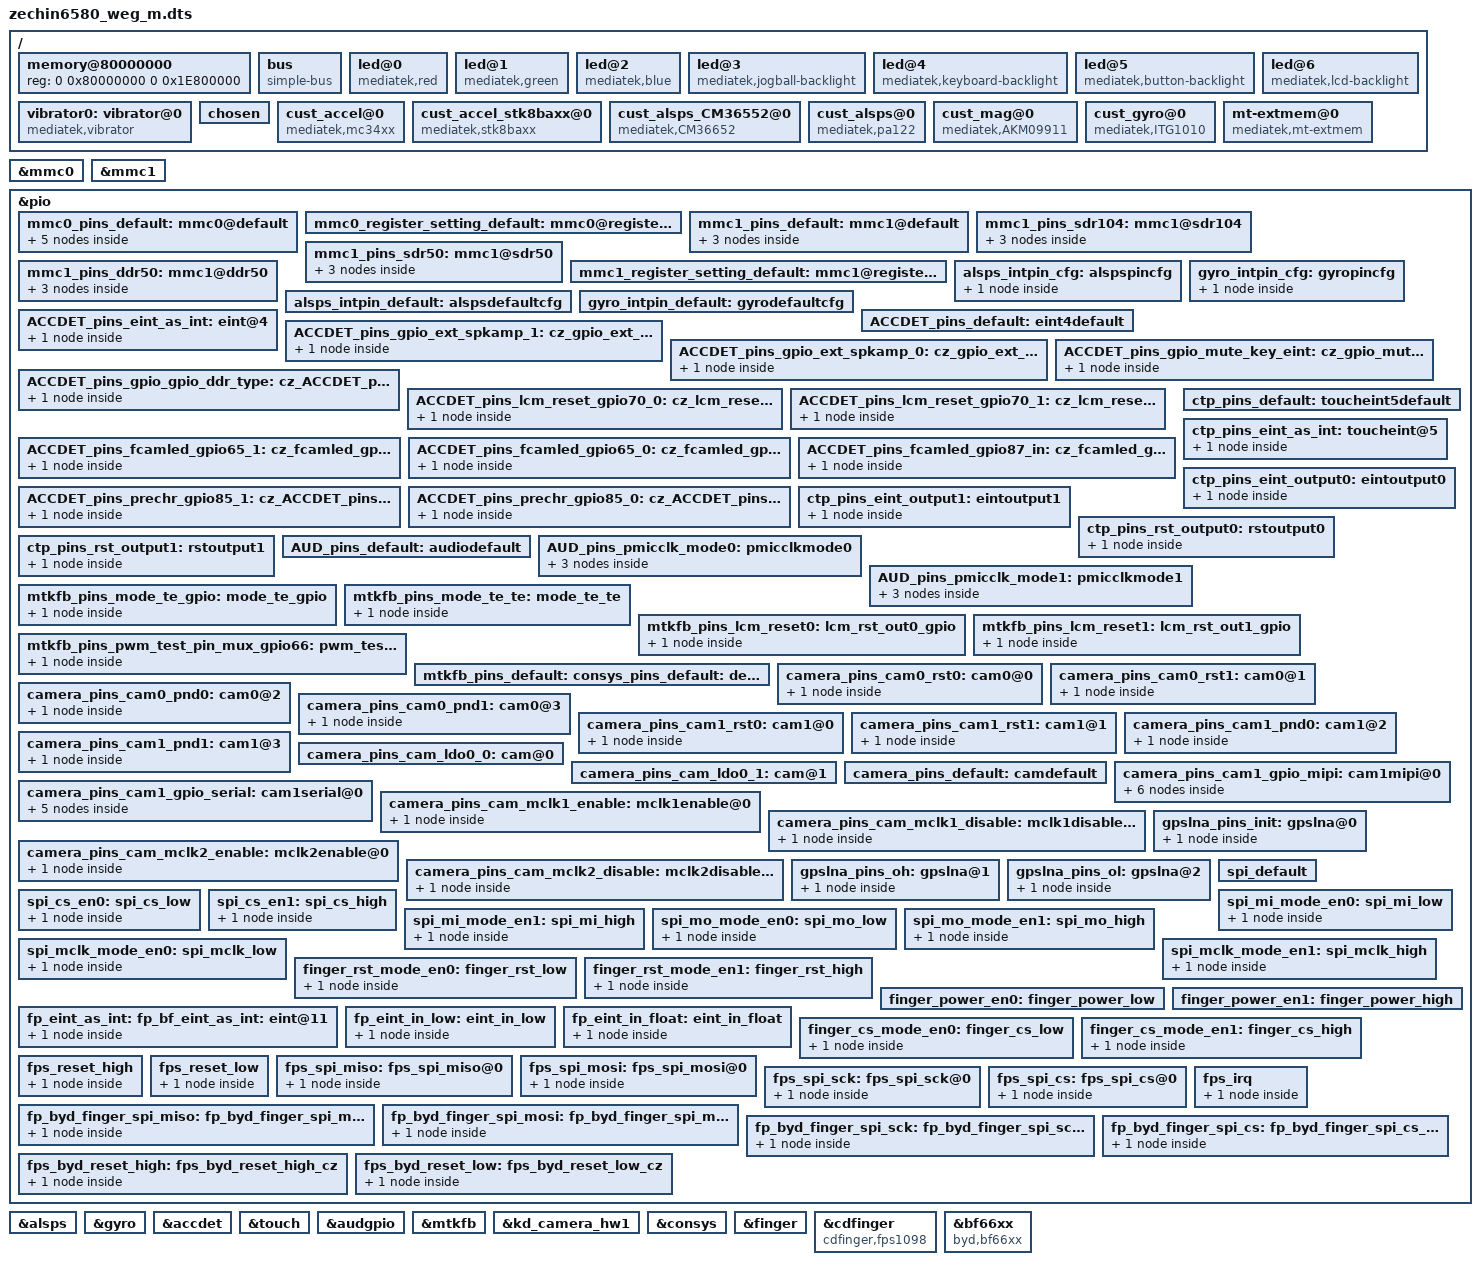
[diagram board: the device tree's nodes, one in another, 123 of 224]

/dts-v1/;

#include "mt6580.dtsi"

/ {
	memory@80000000 {
		device_type = "memory";
		reg = <0 0x80000000 0 0x1E800000>;
	};

	bus {
		compatible = "simple-bus";
		#address-cells = <1>;
		#size-cells = <1>;
		ranges = <0 0 0 0xffffffff>;
	};

	led@0 {
		compatible = "mediatek,red";
		led_mode = <0>;
		data = <1>;
		pwm_config = <0 0 0 0 0>;
	};
	led@1 {
		compatible = "mediatek,green";
		led_mode = <0>;
		data = <1>;
		pwm_config = <0 0 0 0 0>;
	};
	led@2 {
		compatible = "mediatek,blue";
		led_mode = <0>;
		data = <1>;
		pwm_config = <0 0 0 0 0>;
	};
	led@3 {
		compatible = "mediatek,jogball-backlight";
		led_mode = <0>;
		data = <1>;
		pwm_config = <0 0 0 0 0>;
	};
	led@4 {
		compatible = "mediatek,keyboard-backlight";
		led_mode = <0>;
		data = <1>;
		pwm_config = <0 0 0 0 0>;
	};
	led@5 {
		compatible = "mediatek,button-backlight";
		led_mode = <0>;
		data = <1>;
		pwm_config = <0 0 0 0 0>;
	};
	led@6 {
		compatible = "mediatek,lcd-backlight";
		led_mode = <5>;
		data = <1>;
		pwm_config = <0 0 0 0 0>;
	};
	vibrator0:vibrator@0 {
		compatible = "mediatek,vibrator";
		vib_timer = <25>;
		vib_limit = <9>;
		vib_vol= <7>;
	};

	   /* chosen */
	   chosen {
	bootargs = "console=tty0 console=ttyMT0,921600n1 root=/dev/ram initrd=0x84000000,0x400000 loglevel=8";
		/* fpga may has no lk, we need to specify display info here */
		/* fb buffer is reserved using this dts by memory node above */
		atag,videolfb-fb_base = <0x9E800000>;
		atag,videolfb-islcmfound = <1>;
		atag,videolfb-fps= <6000>;
		atag,videolfb-vramSize= <0x01800000>;
		atag,videolfb-lcmname= "nt35590_AUO";
	   };
	 /*  start sensor cz mod direction from 2 to 3(h339_80) s89 */
	 /*  start sensor */
		cust_accel@0 {
		compatible				= "mediatek,MC3410";
		i2c_num				= <2>;
		i2c_addr				= <0x4c 0 0 0>;
		direction				= <2>;
		power_id				= <0xffff>;
		power_vol				= <0>;
		firlen					= <0>;
		is_batch_supported			= <0>;
			};


		cust_accel@0 {
		compatible				= "mediatek,MC3XXX";
		i2c_num				= <2>;
		i2c_addr				= <0x4c 0 0 0>;
		direction				= <6>;
		power_id				= <0xffff>;
		power_vol				= <0>;
		firlen					= <0>;
		is_batch_supported			= <0>;
			};

/* sensor standardization */

	cust_accel@0 {
		compatible 				= "mediatek,mc34xx";
		i2c_num 				= <2>;
		i2c_addr 				= <0x4c 0 0 0>;
		direction 				= <0>;
		power_id 				= <0xffff>;
		power_vol 				= <0>;
		firlen					= <0>;
		is_batch_supported		= <0>;
	};

			/* 4 before */
		cust_accel_stk8baxx@0 {
		compatible				= "mediatek,stk8baxx";
		i2c_num				= <2>;
		i2c_addr				= <0x18 0 0 0>;
		direction				= <0>;
		power_id				= <0xffff>;
		power_vol				= <0>;
		firlen					= <2>;
		is_batch_supported			= <0>;
			};

		cust_alsps_CM36552@0 {
		compatible				= "mediatek,CM36652";
		i2c_num				= <2>;
		i2c_addr				= <0x60 0 0 0>;
		polling_mode_ps			= <0>;
		polling_mode_als		= <1>;
		power_id				= <0xffff>;
		power_vol				= <0>;
/* Total has 15 level*/
	als_level = <0 125 319 525 1091 2480 3058 5115 8589 10769 12857 17807 22091 65535 65535>;
/*  Total has 16 range*/
	als_value = <0 133 303 504 1002 2003 3006 5003 8002 10000 12000 16000 20000 20000 20000 20000>;
		ps_threshold_high		=  <26>;
		ps_threshold_low		=  <21>;
		is_batch_supported_ps	= <0>;
		is_batch_supported_als	= <0>;
		};



		cust_alsps@0 {
		compatible				= "mediatek,pa122";
		i2c_num				= <2>;
		i2c_addr				= <0x1e 0 0 0>;
		polling_mode_ps			= <0>;
		polling_mode_als		= <1>;
		power_id				= <0xffff>;
		power_vol				= <0>;
		als_level = <0 328 861 1377 3125 7721 7767 12621 23062 28430 33274 47116 57694 57694 65535>;
		als_value = <0 133 304 502 1004 2005 3058 5005 8008 10010 12000 16000 20000 20000 20000 20000>;
		ps_threshold_high		=  <34>;
		ps_threshold_low		=  <28>;
		is_batch_supported_ps	= <0>;
		is_batch_supported_als	= <0>;
		};

			cust_mag@0 {
		compatible				= "mediatek,AKM09911";
		i2c_num				= <2>;
		i2c_addr				= <0x0D 0 0 0>;
		direction				= <4>;
		power_id				= <0xffff>;
		power_vol				= <0>;
		is_batch_supported	= <0>;
			};

			cust_gyro@0 {
		compatible				= "mediatek,ITG1010";
		i2c_num				= <2>;
		i2c_addr				= <0x68 0 0 0>;
		direction				= <1>;
		power_id				= <0xffff>;
		power_vol				= <0>;
		firlen					= <0>;
		is_batch_supported	= <0>;
			};


	 /* end sensor */

	mt-extmem@0 {
		compatible = "mediatek,mt-extmem";
	};
};

/* mmc start */
&mmc0 {
	clk_src = /bits/ 8 <MSDC0_CLKSRC_208MHZ>;
	bus-width = <8>;
	max-frequency = <208000000>;
	cap-mmc-highspeed;
	msdc-sys-suspend;
	mmc-hs200-1_8v;
	non-removable;
	pinctl = <&mmc0_pins_default>;
	register_setting = <&mmc0_register_setting_default>;
	host_function = /bits/ 8 <MSDC_EMMC>;
	bootable;
	status = "okay";
};

&mmc1 {
	clk_src = /bits/ 8 <MSDC1_CLKSRC_187MHZ>;
	bus-width = <4>;
	max-frequency = <208000000>;
	msdc-sys-suspend;
	cap-sd-highspeed;
	sd-uhs-sdr12;
	sd-uhs-sdr25;
	sd-uhs-sdr50;
	sd-uhs-sdr104;
	pinctl = <&mmc1_pins_default>;
	pinctl_sdr104 = <&mmc1_pins_sdr104>;
	pinctl_sdr50 = <&mmc1_pins_sdr50>;
	pinctl_ddr50 = <&mmc1_pins_ddr50>;
	register_setting = <&mmc1_register_setting_default>;
	host_function = /bits/ 8 <MSDC_SD>;
	cd_level = /bits/ 8 <MSDC_CD_HIGH>;
	cd-gpios = <&pio 15 0>;
	/*non-removable;*/
	status = "okay";
};

&pio {
	mmc0_pins_default: mmc0@default {
		pins_cmd {
			drive-strength = /bits/ 8 <2>;
		};
		pins_dat {
			drive-strength = /bits/ 8 <2>;
		};
		pins_clk {
			drive-strength = /bits/ 8 <2>;
		};
		pins_rst {
			drive-strength = /bits/ 8 <2>;
		};
		pins_ds {
			drive-strength = /bits/ 8 <2>;
		};
	};

	mmc0_register_setting_default: mmc0@register_default {
		dat0rddly      = /bits/ 8 <0>;
		dat1rddly      = /bits/ 8 <0>;
		dat2rddly      = /bits/ 8 <0>;
		dat3rddly      = /bits/ 8 <0>;
		dat4rddly      = /bits/ 8 <0>;
		dat5rddly      = /bits/ 8 <0>;
		dat6rddly      = /bits/ 8 <0>;
		dat7rddly      = /bits/ 8 <0>;
		datwrddly      = /bits/ 8 <0>;
		cmdrrddly      = /bits/ 8 <0>;
		cmdrddly       = /bits/ 8 <0>;
		cmd_edge = /bits/ 8 <MSDC_SMPL_FALLING>;
		rdata_edge = /bits/ 8 <MSDC_SMPL_FALLING>;
		wdata_edge = /bits/ 8 <MSDC_SMPL_FALLING>;

		ett-hs200-cells = <12>;
		ett-hs200-default = <OFFSET_MSDC_PATCH_BIT0	MSDC_PB0_INT_DAT_LATCH_CK_SEL 0x0
			OFFSET_MSDC_PATCH_BIT0  MSDC_PB0_CKGEN_MSDC_DLY_SEL   0x0
			OFFSET_MSDC_PATCH_BIT1  MSDC_PB1_CMD_RSP_TA_CNTR      0x1
			OFFSET_MSDC_IOCON       MSDC_IOCON_RSPL               0x1
			OFFSET_MSDC_PAD_TUNE0   MSDC_PAD_TUNE0_CMDRDLY        0x0
			OFFSET_MSDC_PAD_TUNE0   MSDC_PAD_TUNE0_CMDRRDLY       0x0
			OFFSET_MSDC_PATCH_BIT1  MSDC_PB1_WRDAT_CRCS_TA_CNTR   0x1
			OFFSET_MSDC_PAD_TUNE0   MSDC_PAD_TUNE0_DATWRDLY       0x0
			OFFSET_MSDC_IOCON       MSDC_IOCON_W_D_SMPL           0x1
			OFFSET_MSDC_DAT_RDDLY0  MSDC_DAT_RDDLY0_D0            0x0
			OFFSET_MSDC_PAD_TUNE0   MSDC_PAD_TUNE0_DATRRDLY       0x0
			OFFSET_MSDC_PATCH_BIT0  MSDC_PB0_RD_DAT_SEL           0x1>;
	};

	mmc1_pins_default: mmc1@default {
		pins_cmd {
			drive-strength = /bits/ 8 <3>;
		};
		pins_dat {
			drive-strength = /bits/ 8 <3>;
		};
		pins_clk {
			drive-strength = /bits/ 8 <3>;
		};
	};

	mmc1_pins_sdr104: mmc1@sdr104 {
		pins_cmd {
			drive-strength = /bits/ 8 <2>;
		};
		pins_dat {
			drive-strength = /bits/ 8 <2>;
		};
		pins_clk {
			drive-strength = /bits/ 8 <3>;
		};
	};

	mmc1_pins_sdr50: mmc1@sdr50 {
		pins_cmd {
			drive-strength = /bits/ 8 <2>;
		};
		pins_dat {
			drive-strength = /bits/ 8 <2>;
		};
		pins_clk {
			drive-strength = /bits/ 8 <3>;
		};
	};

	mmc1_pins_ddr50: mmc1@ddr50 {
		pins_cmd {
			drive-strength = /bits/ 8 <2>;
		};
		pins_dat {
			drive-strength = /bits/ 8 <2>;
		};
		pins_clk {
			drive-strength = /bits/ 8 <3>;
		};
	};

	mmc1_register_setting_default: mmc1@register_default {
		dat0rddly      = /bits/ 8 <0>;
		dat1rddly      = /bits/ 8 <0>;
		dat2rddly      = /bits/ 8 <0>;
		dat3rddly      = /bits/ 8 <0>;
		datwrddly      = /bits/ 8 <0>;
		cmdrrddly      = /bits/ 8 <0>;
		cmdrddly       = /bits/ 8 <0>;
		cmd_edge = /bits/ 8 <MSDC_SMPL_FALLING>;
		rdata_edge = /bits/ 8 <MSDC_SMPL_FALLING>;
		wdata_edge = /bits/ 8 <MSDC_SMPL_FALLING>;
	};
};
/* mmc end */

&pio {
	alsps_intpin_cfg: alspspincfg {
	    pins_cmd_dat {
			pins = <PINMUX_GPIO6__FUNC_EINT6>;
			slew-rate = <0>;
			bias-pull-up = <00>;
		};
	};
	alsps_intpin_default: alspsdefaultcfg {
	};
	gyro_intpin_cfg: gyropincfg {
	    pins_cmd_dat {
			pins = <PINMUX_GPIO1__FUNC_GPIO1>;
			slew-rate = <0>;
			bias-pull-down = <00>;
		};
	};
	gyro_intpin_default: gyrodefaultcfg {
	};
};
&alsps {
	pinctrl-names = "pin_default", "pin_cfg";
	pinctrl-0 = <&alsps_intpin_default>;
	pinctrl-1 = <&alsps_intpin_cfg>;
	status = "okay";
};
&gyro {
	pinctrl-names = "pin_default", "pin_cfg";
	pinctrl-0 = <&gyro_intpin_default>;
	pinctrl-1 = <&gyro_intpin_cfg>;
	status = "okay";
};
/*cz add for external amp gpio*/
&accdet {
	accdet-mic-vol = <7>;
	headset-mode-setting = <0x500 0x200 1 0x1F0 0x800 0x800 0x20>;
	accdet-plugout-debounce = <20>;
	/*1:ACC mode, 2:low cost without in bias, 6:low cost with in bias*/
	accdet-mic-mode = <1>;
	/*0--MD_MAX--UP_MAX--DW_MAX*/
	headset-three-key-threshold = <0 90 240 500>;
	/*0--MD_MAX--VOICE_MAX--UP_MAX--DW_MAX*/
	headset-four-key-threshold = <0 59 123 195 450>;
	/* ACCDET GPIO standardization ACC mode use */
	pinctrl-names = "default", "state_eint_as_int", "gpio_ext_spkamp_1", "gpio_ext_spkamp_0", "gpio_mute_key_eint", "lcm_reset_gpio70_0", "lcm_reset_gpio70_1", "fcamled_gpio65_1", "fcamled_gpio65_0", "fcamled_gpio87_in",
					"prechr_gpio85_1", "prechr_gpio85_0";
	pinctrl-0 = <&ACCDET_pins_default>;
	pinctrl-1 = <&ACCDET_pins_eint_as_int>;
	/*cz add for external amp gpio*/
	pinctrl-2 = <&ACCDET_pins_gpio_ext_spkamp_1>;
	pinctrl-3 = <&ACCDET_pins_gpio_ext_spkamp_0>;
	pinctrl-4 = <&ACCDET_pins_gpio_mute_key_eint>;
	/*pinctrl-5 = <&ACCDET_pins_gpio_gpio_ddr_type>;*/
	pinctrl-5 = <&ACCDET_pins_lcm_reset_gpio70_0>;
	pinctrl-6 = <&ACCDET_pins_lcm_reset_gpio70_1>;
	pinctrl-7 = <&ACCDET_pins_fcamled_gpio65_1>;
	pinctrl-8 = <&ACCDET_pins_fcamled_gpio65_0>;
	pinctrl-9 = <&ACCDET_pins_fcamled_gpio87_in>;
	pinctrl-10 = <&ACCDET_pins_prechr_gpio85_1>;
	pinctrl-11 = <&ACCDET_pins_prechr_gpio85_0>;

	gpio_087_board_detect = <&pio 87 0>;

	/*gpio7==fps_rst*/
	gpio_007 = <&pio 7 0>;
	
	gpio_mute = <&pio 12 0>;
	/* gpio3==sec_dat	gpio6==sec_clk */
	gpio_003_dat = <&pio 18 0>; 
	gpio_006_clk = <&pio 16 0>;
	/*gpio_084 s89v1.2==nc*/
	gpio70_lcm_reset = <&pio 70 0>;
	gpio_084_lcm_bias_en = <&pio 84 0>;
	/* cz for s89 */
	
/*	gpio_018_dat = <&pio 18 0>;*/
/*  gpio_019_clk = <&pio 19 0>;*/
	
	gpio_020_2g3g_sel = <&pio 20 0>;
	gpio_021_usb_en = <&pio 21 0>;	
	gpio_011_usb_en2 = <&pio 19 0>;
	/* gpio_017_fps_en = <&pio 17 0>; */
	/* fps int gpio11 */
	
	status = "okay";
};
&pio {
	ACCDET_pins_default: eint4default {
	};
	ACCDET_pins_eint_as_int: eint@4 {
		pins_cmd_dat {
			pins = <PINMUX_GPIO4__FUNC_EINT4>;
			slew-rate = <0>;
			bias-disable;
		};
	};
	/*cz add for amp*/
	ACCDET_pins_gpio_ext_spkamp_1: cz_gpio_ext_spkamp_1 {
		pins_cmd_dat {
			pins = <PINMUX_GPIO10__FUNC_GPIO10>;
			slew-rate = <1>;
			bias-disable;
			output-high;
		};
	};	
	ACCDET_pins_gpio_ext_spkamp_0: cz_gpio_ext_spkamp_0 {
		pins_cmd_dat {
			pins = <PINMUX_GPIO10__FUNC_GPIO10>;
			slew-rate = <1>;
			bias-disable;
			output-low;
		};
	};	
	ACCDET_pins_gpio_mute_key_eint: cz_gpio_mute_key_eint {
		pins_cmd_dat {
			pins = <PINMUX_GPIO12__FUNC_EINT12>;
			slew-rate = <0>;
			bias-disable;
		};
	};	

	ACCDET_pins_gpio_gpio_ddr_type: cz_ACCDET_pins_gpio_gpio_ddr_type {
		pins_cmd_dat {
			pins = <PINMUX_GPIO18__FUNC_GPIO18>;
			slew-rate = <0>;
			bias-pull-up = <11>;
		};
	};	


	ACCDET_pins_lcm_reset_gpio70_0: cz_lcm_reset_gpio70_0 {
		pins_cmd_dat {
			pins = <PINMUX_GPIO70__FUNC_GPIO70>;
			slew-rate = <1>;
			bias-disable;
			output-low;
		};
	};	

	ACCDET_pins_lcm_reset_gpio70_1: cz_lcm_reset_gpio70_1 {
		pins_cmd_dat {
			pins = <PINMUX_GPIO70__FUNC_GPIO70>;
			slew-rate = <1>;
			bias-disable;
			output-high;
		};
	};	

	ACCDET_pins_fcamled_gpio65_1: cz_fcamled_gpio65_1 {
		pins_cmd_dat {
			pins = <PINMUX_GPIO65__FUNC_GPIO65>;
			slew-rate = <1>;
			bias-disable;
			output-high;
		};
	};	


	ACCDET_pins_fcamled_gpio65_0: cz_fcamled_gpio65_0 {
		pins_cmd_dat {
			pins = <PINMUX_GPIO65__FUNC_GPIO65>;
			slew-rate = <1>;
			bias-disable;
			output-low;
		};
	};	

	ACCDET_pins_fcamled_gpio87_in: cz_fcamled_gpio87_in {
		pins_cmd_dat {
			pins = <PINMUX_GPIO87__FUNC_GPIO87>;
			slew-rate = <0>;
			bias-pull-up = <11>;
		};
	};

	ACCDET_pins_prechr_gpio85_1: cz_ACCDET_pins_prechr_gpio85_1 {
		pins_cmd_dat {
			pins = <PINMUX_GPIO85__FUNC_GPIO85>;
			slew-rate = <1>;
			bias-disable;
			output-high;
		};
	};	

	ACCDET_pins_prechr_gpio85_0: cz_ACCDET_pins_prechr_gpio85_0 {
		pins_cmd_dat {
			pins = <PINMUX_GPIO85__FUNC_GPIO85>;
			slew-rate = <1>;
			bias-disable;
			output-low;
		};
	};	
	
	/*add end.*/
};
/*ACCDET END*/
/* TOUCH GPIO standardization */
&touch {
	tpd-resolution = <720 1440>;
	/*use-tpd-button = <0>;*/
	/*cz mod mtk before tpd-key-num = <3>;*/
	/*tpd-key-local= <139 172 158 0>;*/
	/*tpd-key-dim-local = <90 883 100 40 230 883 100 40 370 883 100 40 0 0 0 0>;*/
	use-tpd-button = <1>;
	tpd-key-num = <1>;
	/*158==KEY_BACK*/
	/*100==KEY_RIGHTALT*/
	/*64==KEY_F6*/
	/*102==KEY_HOME*/	
	tpd-key-local= <102 0 0 0>;
	/* tpd-key-local= <64 0 0 0>; */
	/*(400, 1866)==h339_80_hd*/
	/*s89==90,1000*/
	tpd-key-dim-local = <36 1476 90 40 0 0 0 0 0 0 0 0 0 0 0 0>;
	/*tpd-key-dim-local = <300 1400 100 40 0 0 0 0 0 0 0 0 0 0 0 0>;*/
	tpd-max-touch-num = <5>;
	tpd-filter-enable = <1>;
	tpd-filter-pixel-density = <93>;
	tpd-filter-custom-prameters = <0 0 0 0 0 0 0 0 0 0 0 0>;
	tpd-filter-custom-speed = <0 0 0>;
	pinctrl-names = "default", "state_eint_as_int", "state_eint_output0", "state_eint_output1",
		"state_rst_output0", "state_rst_output1";
	pinctrl-0 = <&ctp_pins_default>;
	pinctrl-1 = <&ctp_pins_eint_as_int>;
	pinctrl-2 = <&ctp_pins_eint_output0>;
	pinctrl-3 = <&ctp_pins_eint_output1>;
	pinctrl-4 = <&ctp_pins_rst_output0>;
	pinctrl-5 = <&ctp_pins_rst_output1>;
	status = "okay";
};
&pio {
	ctp_pins_default: toucheint5default {
	};
	ctp_pins_eint_as_int: toucheint@5 {
		pins_cmd_dat {
			pins = <PINMUX_GPIO5__FUNC_EINT5>;
			slew-rate = <0>;
			bias-disable;
		};
	};
	ctp_pins_eint_output0: eintoutput0 {
		pins_cmd_dat {
			pins = <PINMUX_GPIO5__FUNC_GPIO5>;
			slew-rate = <1>;
			output-low;
		};
	};
	ctp_pins_eint_output1: eintoutput1 {
		pins_cmd_dat {
			pins = <PINMUX_GPIO5__FUNC_GPIO5>;
			slew-rate = <1>;
			output-high;
		};
	};
	ctp_pins_rst_output0: rstoutput0 {
		pins_cmd_dat {
			pins = <PINMUX_GPIO9__FUNC_GPIO9>;
			slew-rate = <1>;
			output-low;
		};
	};
	ctp_pins_rst_output1: rstoutput1 {
		pins_cmd_dat {
			pins = <PINMUX_GPIO9__FUNC_GPIO9>;
			slew-rate = <1>;
			output-high;
		};
	};
};
/* TOUCH end */

/* AUDIO GPIO standardization */
&audgpio {
	pinctrl-names = "default", "audpmicclk-mode0", "audpmicclk-mode1";
	pinctrl-0 = <&AUD_pins_default>;
	pinctrl-1 = <&AUD_pins_pmicclk_mode0>;
	pinctrl-2 = <&AUD_pins_pmicclk_mode1>;
	status = "okay";
};
&pio {
	AUD_pins_default: audiodefault {
	};
	AUD_pins_pmicclk_mode0: pmicclkmode0 {
		pins_cmd0_dat {
			pins = <PINMUX_GPIO26__FUNC_GPIO26>;
		};
		pins_cmd1_dat {
			pins = <PINMUX_GPIO28__FUNC_GPIO28>;
		};
		pins_cmd2_dat {
			pins = <PINMUX_GPIO27__FUNC_GPIO27>;
		};
	};
	AUD_pins_pmicclk_mode1: pmicclkmode1 {
		pins_cmd0_dat {
			pins = <PINMUX_GPIO26__FUNC_AUD_CLK_MOSI>;
		};
		pins_cmd1_dat {
			pins = <PINMUX_GPIO28__FUNC_AUD_DAT_MISO>;
		};
		pins_cmd2_dat {
			pins = <PINMUX_GPIO27__FUNC_AUD_DAT_MOSI>;
		};
	};
};
/* AUDIO end */

/* DISPSYS GPIO standardization */
&pio {

	mtkfb_pins_mode_te_gpio: mode_te_gpio {
		pins_cmd_dat {
			pins = <PINMUX_GPIO68__FUNC_GPIO68>;
		};
	};

	mtkfb_pins_mode_te_te: mode_te_te {
		pins_cmd_dat {
			pins = <PINMUX_GPIO68__FUNC_DSI_TE>;
		};
	};

	mtkfb_pins_lcm_reset0: lcm_rst_out0_gpio {
		pins_cmd_dat {
			pins = <PINMUX_GPIO70__FUNC_LCM_RST>;
			slew-rate = <1>;
			output-low;
		};
	};

	mtkfb_pins_lcm_reset1: lcm_rst_out1_gpio {
		pins_cmd_dat {
			pins = <PINMUX_GPIO70__FUNC_LCM_RST>;
			slew-rate = <1>;
			output-high;
		};
	};

	mtkfb_pins_pwm_test_pin_mux_gpio66: pwm_test_pin_mux_gpio66 {
		pins_cmd_dat {
			pins = <PINMUX_GPIO66__FUNC_DISP_PWM>;
			slew-rate = <1>;
		};
	};

	mtkfb_pins_default: default {
	};
};

&mtkfb {
	pinctrl-names = "default", "mode_te_gpio", "mode_te_te",
			"lcm_rst_out0_gpio", "lcm_rst_out1_gpio",
			"pwm_test_pin_mux_gpio66";
	pinctrl-0 = <&mtkfb_pins_default>;
	pinctrl-1 = <&mtkfb_pins_mode_te_gpio>;
	pinctrl-2 = <&mtkfb_pins_mode_te_te>;
	pinctrl-3 = <&mtkfb_pins_lcm_reset0>;
	pinctrl-4 = <&mtkfb_pins_lcm_reset1>;
	pinctrl-5 = <&mtkfb_pins_pwm_test_pin_mux_gpio66>;
	status = "okay";
};
/* DISPSYS GPIO standardization end */
/* CAMERA GPIO standardization */
&pio {
	camera_pins_cam0_rst0: cam0@0 {
	    pins_cmd_dat {
			pins = <PINMUX_GPIO73__FUNC_GPIO73>;/*GPIO_CAMERA_CMRST_PIN*/
			slew-rate = <1>; /*direction 0:in, 1:out*/
			output-low;/*direction out used only. output_low or high*/
		};
	};
	camera_pins_cam0_rst1: cam0@1 {
	    pins_cmd_dat {
			pins = <PINMUX_GPIO73__FUNC_GPIO73>;/*GPIO_CAMERA_CMRST_PIN*/
			slew-rate = <1>;
			output-high;
		};
	};
	camera_pins_cam0_pnd0: cam0@2 {
	    pins_cmd_dat {
			pins = <PINMUX_GPIO71__FUNC_GPIO71>;/*GPIO_CAMERA_CMPDN_PIN*/
			slew-rate = <1>;
			output-low;
		};
	};
	camera_pins_cam0_pnd1: cam0@3 {
	    pins_cmd_dat {
			pins = <PINMUX_GPIO71__FUNC_GPIO71>;/*GPIO_CAMERA_CMPDN_PIN*/
			slew-rate = <1>;
			output-high;
		};
	};
	camera_pins_cam1_rst0: cam1@0 {
	    pins_cmd_dat {
			pins = <PINMUX_GPIO76__FUNC_GPIO76>;/*GPIO_CAMERA_CMRST1_PIN*/
			slew-rate = <1>; /*direction 0:in, 1:out*/
			output-low;/*direction out used only. output_low or high*/
		};
	};
	camera_pins_cam1_rst1: cam1@1 {
	    pins_cmd_dat {
			pins = <PINMUX_GPIO76__FUNC_GPIO76>;/*GPIO_CAMERA_CMRST1_PIN*/
			slew-rate = <1>;
			output-high;
		};
	};
	camera_pins_cam1_pnd0: cam1@2 {
	    pins_cmd_dat {
			pins = <PINMUX_GPIO74__FUNC_GPIO74>;/*GPIO_CAMERA_CMPDN1_PIN*/
			slew-rate = <1>;
			output-low;
		};
	};
	camera_pins_cam1_pnd1: cam1@3 {
	    pins_cmd_dat {
			pins = <PINMUX_GPIO74__FUNC_GPIO74>;/*GPIO_CAMERA_CMPDN1_PIN*/
			slew-rate = <1>;
			output-high;
		};
	};
	camera_pins_cam_ldo0_0: cam@0 {
	};
	camera_pins_cam_ldo0_1: cam@1 {
	};
	camera_pins_default: camdefault {
	};
	camera_pins_cam1_gpio_serial: cam1serial@0{
	    pins_cmd_dat {
			pins = <PINMUX_GPIO35__FUNC_CMCSK>;
		};
	    pins_cmd_dat1 {
			pins = <PINMUX_GPIO36__FUNC_CMCSD0>;
		};
	    pins_cmd_dat2 {
			pins = <PINMUX_GPIO37__FUNC_CMCSD1>;
		};
	    pins_cmd_dat3 {
			pins = <PINMUX_GPIO38__FUNC_CMCSD2>;
		};
	    pins_cmd_dat4 {
			pins = <PINMUX_GPIO39__FUNC_CMCSD3>;
		};
	};
	camera_pins_cam1_gpio_mipi: cam1mipi@0{
	    pins_cmd_dat {
			pins = <PINMUX_GPIO35__FUNC_PAD_RDP0_A>;
		};
	    pins_cmd_dat1 {
			pins = <PINMUX_GPIO36__FUNC_PAD_RDN0_A>;
		};
	    pins_cmd_dat2 {
			pins = <PINMUX_GPIO37__FUNC_PAD_RDP1_A>;
		};
	    pins_cmd_dat3 {
			pins = <PINMUX_GPIO38__FUNC_PAD_RDN1_A>;
		};
	    pins_cmd_dat4 {
			pins = <PINMUX_GPIO39__FUNC_PAD_RCP_A>;
		};
	    pins_cmd_dat5 {
			pins = <PINMUX_GPIO40__FUNC_PAD_RCN_A>;
		};
	};
	camera_pins_cam_mclk1_enable: mclk1enable@0{
		pins_cmd_dat {
			pins = <PINMUX_GPIO72__FUNC_CAM_CLK0>;
		};
	};
	camera_pins_cam_mclk1_disable: mclk1disable@0{
	   pins_cmd_dat {
			pins = <PINMUX_GPIO72__FUNC_GPIO72>;
		};
	};
	camera_pins_cam_mclk2_enable: mclk2enable@0{
		pins_cmd_dat {
			pins = <PINMUX_GPIO75__FUNC_CAM_CLK1>;
		};
	};
	camera_pins_cam_mclk2_disable: mclk2disable@0{
		pins_cmd_dat {
			pins = <PINMUX_GPIO75__FUNC_GPIO75>;
		};
	};


};
&kd_camera_hw1 {
	pinctrl-names = "default", "cam0_rst0", "cam0_rst1", "cam0_pnd0", "cam0_pnd1",
				   "cam1_rst0", "cam1_rst1", "cam1_pnd0", "cam1_pnd1",
				   "cam_ldo0_0", "cam_ldo0_1", "cam1_gpio_serial", "cam1_gpio_mipi",
				   "cam_mclk1_enable","cam_mclk1_disable",
				   "cam_mclk2_enable","cam_mclk2_disable";
	pinctrl-0 = <&camera_pins_default>;
	pinctrl-1 = <&camera_pins_cam0_rst0>;
	pinctrl-2 = <&camera_pins_cam0_rst1>;
	pinctrl-3 = <&camera_pins_cam0_pnd0>;
	pinctrl-4 = <&camera_pins_cam0_pnd1>;
	pinctrl-5 = <&camera_pins_cam1_rst0>;
	pinctrl-6 = <&camera_pins_cam1_rst1>;
	pinctrl-7 = <&camera_pins_cam1_pnd0>;
	pinctrl-8 = <&camera_pins_cam1_pnd1>;
	pinctrl-9 = <&camera_pins_cam_ldo0_0>;
	pinctrl-10 = <&camera_pins_cam_ldo0_1>;
	pinctrl-11 = <&camera_pins_cam1_gpio_serial>;
	pinctrl-12 = <&camera_pins_cam1_gpio_mipi>;
	pinctrl-13 = <&camera_pins_cam_mclk1_enable>;
	pinctrl-14 = <&camera_pins_cam_mclk1_disable>;
	pinctrl-15 = <&camera_pins_cam_mclk2_enable>;
	pinctrl-16 = <&camera_pins_cam_mclk2_disable>;

	status = "okay";

};
/* CAMERA GPIO end */

/* CONSYS GPIO standardization cz mod from gpio67 to gpio8*/
&pio {
	consys_pins_default: default {

	};

	gpslna_pins_init: gpslna@0 {

		pins_cmd_dat {
			pins = <PINMUX_GPIO8__FUNC_GPIO8>;
			slew-rate = <0>;
			bias-disable;
			output-low;
		};
	};

	gpslna_pins_oh: gpslna@1 {

		pins_cmd_dat {
			pins = <PINMUX_GPIO8__FUNC_GPIO8>;
			slew-rate = <1>;
			output-high;
		};
	};

	gpslna_pins_ol: gpslna@2 {

		pins_cmd_dat {
			pins = <PINMUX_GPIO8__FUNC_GPIO8>;
			slew-rate = <1>;
			output-low;
		};
	};

};

&consys {
	pinctrl-names = "default", "gps_lna_state_init", "gps_lna_state_oh", "gps_lna_state_ol";
	pinctrl-0 = <&consys_pins_default>;
	pinctrl-1 = <&gpslna_pins_init>;
	pinctrl-2 = <&gpslna_pins_oh>;
	pinctrl-3 = <&gpslna_pins_ol>;
	status = "okay";

};
/* CONSYS end */

//cz add for icn7157
/*ricky for spi finger ,gooidx*/

&pio {
	spi_default: spi_default {
	};

	spi_cs_en0: spi_cs_low {
		pins_cmd_dat {
			pins = <PINMUX_GPIO0__FUNC_SPI1_CS>;
			slew-rate = <1>;
			output-low;
		};
	};
	spi_cs_en1: spi_cs_high {
		pins_cmd_dat {
			pins = <PINMUX_GPIO0__FUNC_SPI1_CS>;
			slew-rate = <1>;
			output-high;
		};
	};	
	spi_mi_mode_en0: spi_mi_low {
		pins_cmd_dat {
			pins = <PINMUX_GPIO3__FUNC_SPI1_MISO>;
			slew-rate = <0>;
			bias-pull-up = <00>;
		};
	};
	spi_mi_mode_en1: spi_mi_high {
		pins_cmd_dat {
			pins = <PINMUX_GPIO3__FUNC_SPI1_MISO>;
			bias-disable;
		};
	};	
	spi_mo_mode_en0: spi_mo_low {
		pins_cmd_dat {
			pins = <PINMUX_GPIO2__FUNC_SPI1_MOSI>;
			slew-rate = <1>;
			output-low;
		};
	};
	spi_mo_mode_en1: spi_mo_high {
		pins_cmd_dat {
			pins = <PINMUX_GPIO2__FUNC_SPI1_MOSI>;
			slew-rate = <1>;
			output-high;
		};
	};	
		spi_mclk_mode_en0: spi_mclk_low {
		pins_cmd_dat {
			pins = <PINMUX_GPIO1__FUNC_SPI1_SCK>;
			slew-rate = <1>;
			output-low;
		};
	};
	spi_mclk_mode_en1: spi_mclk_high {
		pins_cmd_dat {
			pins = <PINMUX_GPIO1__FUNC_SPI1_SCK>;
			slew-rate = <1>;
			output-high;
		};
	};	

	finger_rst_mode_en0: finger_rst_low {
		pins_cmd_dat {
			pins = <PINMUX_GPIO7__FUNC_GPIO7>;
			slew-rate = <1>;
			output-low;
		};
	};
	finger_rst_mode_en1: finger_rst_high {
		pins_cmd_dat {
			pins = <PINMUX_GPIO7__FUNC_GPIO7>;
			slew-rate = <1>;
			output-high;
		};
	};	
	finger_power_en0: finger_power_low {
	
	};
	finger_power_en1: finger_power_high {
		
	};	
	fp_eint_as_int: eint@11 {
		pins_cmd_dat {
			pins = <PINMUX_GPIO11__FUNC_EINT11>;
			slew-rate = <0>;
			bias-disable;
		};
	};
	fp_eint_in_low: eint_in_low {
		pins_cmd_dat {
			pins = <PINMUX_GPIO11__FUNC_GPIO11>;
			slew-rate = <0>;
			/*bias-pull-down = <00>;*/
			bias-disable;
			
		};
	};
	fp_eint_in_float: eint_in_float {
		pins_cmd_dat {
			pins = <PINMUX_GPIO11__FUNC_GPIO11>;
			slew-rate = <0>;
			bias-disable;
		};
	};	
	/*add for finger fpsensor icn7152l*/
	finger_cs_mode_en0: finger_cs_low {
		pins_cmd_dat {
			pins = <PINMUX_GPIO0__FUNC_GPIO0>;
			slew-rate = <1>;
			output-low;
		};
	};
	finger_cs_mode_en1: finger_cs_high {
		pins_cmd_dat {
			pins = <PINMUX_GPIO0__FUNC_GPIO0>;
			slew-rate = <1>;
			output-high;
		};
	};	
    /*end add*/
};

&finger {
	pinctrl-names = "spi_default", "spi_cs_low","spi_cs_high","spi_mi_low","spi_mi_high",
					"spi_mo_low","spi_mo_high","spi_mclk_low","spi_mclk_high",
					"finger_rst_low","finger_rst_high","finger_power_low","finger_power_high",
					"eint","eint_in_low","eint_in_float","finger_cs_low","finger_cs_high";
	pinctrl-0 = <&spi_default>;
	pinctrl-1 = <&spi_cs_en0>;
	pinctrl-2 = <&spi_cs_en1>;
	pinctrl-3 = <&spi_mi_mode_en0>;
	pinctrl-4 = <&spi_mi_mode_en1>;
	pinctrl-5 = <&spi_mo_mode_en0>;
	pinctrl-6 = <&spi_mo_mode_en1>;
	pinctrl-7 = <&spi_mclk_mode_en0>;
	pinctrl-8 = <&spi_mclk_mode_en1>;
	pinctrl-9 = <&finger_rst_mode_en0>;
	pinctrl-10 = <&finger_rst_mode_en1>;
	pinctrl-11 = <&finger_power_en0>;
	pinctrl-12 = <&finger_power_en1>;	
	pinctrl-13 = <&fp_eint_as_int>;
	pinctrl-14 = <&fp_eint_in_low>;
	pinctrl-15 = <&fp_eint_in_float>;
	pinctrl-16 = <&finger_cs_mode_en0>;
	pinctrl-17 = <&finger_cs_mode_en1>;
	status = "okay";
};
/*xielei for spi finger ,gooidx end*/

/*add for finger fpsensor icn7152l*/
/*end add*/
//add end.
//add cdfinger
&cdfinger {
		compatible = "cdfinger,fps1098";
		reg = <0>;
		interrupt-parent = <&eintc>;
		interrupts = <11 IRQ_TYPE_EDGE_RISING>;
		debounce = <11 0>;
		vdd_ldo_enable = <0>;
		vio_ldo_enable = <0>;
		config_spi_pin = <1>;
		spi-max-frequency = <8000000>;

		pinctrl-names = "fingerprint_reset_high",
			"fingerprint_reset_low",
			"fingerprint_spi_miso",
			"fingerprint_spi_mosi",
			"fingerprint_spi_sck",
			"fingerprint_spi_cs",
			"fingerprint_irq";

		pinctrl-0 = <&fps_reset_high>;
		pinctrl-1 = <&fps_reset_low>;
		pinctrl-2 = <&fps_spi_miso>;
		pinctrl-3 = <&fps_spi_mosi>;
		pinctrl-4 = <&fps_spi_sck>;
		pinctrl-5 = <&fps_spi_cs>;
		pinctrl-6 = <&fps_irq>;
		status = "okay";
	};


&pio {
	fps_reset_high: fps_reset_high {
		pins_cmd_dat {
			pins = <PINMUX_GPIO7__FUNC_GPIO7>;
			slew-rate = <1>;
			bias-disable;
			output-high;
		};
	};
	fps_reset_low: fps_reset_low {
		pins_cmd_dat {
			pins = <PINMUX_GPIO7__FUNC_GPIO7>;
			slew-rate = <1>;
			bias-disable;
			output-low;
		};
	};
	fps_spi_miso:fps_spi_miso@0{
		pins_cmd_dat {
			pins = <PINMUX_GPIO3__FUNC_SPI1_MISO>;
			slew-rate = <0>;
			bias-pull-up = <11>;
			output-low;
		};
	};
	fps_spi_mosi:fps_spi_mosi@0{
		pins_cmd_dat {
			pins = <PINMUX_GPIO2__FUNC_SPI1_MOSI>;
			slew-rate = <1>;
			bias-pull-up = <11>;
			output-low;
		};
	};
	fps_spi_sck:fps_spi_sck@0{
		pins_cmd_dat {
			pins = <PINMUX_GPIO1__FUNC_SPI1_SCK>;
			slew-rate = <1>;
			bias-pull-up = <11>;
			output-low;
		};
	};
	fps_spi_cs:fps_spi_cs@0{
		pins_cmd_dat {
			pins = <PINMUX_GPIO0__FUNC_GPIO0>;
			slew-rate = <1>;
			bias-pull-up = <11>;
			output-low;
		};
	};
	fps_irq: fps_irq {
		pins_cmd_dat {
			pins = <PINMUX_GPIO11__FUNC_GPIO11>;
			slew-rate = <0>;
			bias-disable;
			output-low;
		};
	};
};

/*byd add begin*/
&bf66xx{
		compatible = "byd,bf66xx";
	
		pinctrl-names = "spi_default","bf_eint_as_int","byd_finger_spi_miso","byd_finger_spi_mosi","byd_finger_spi_sck",
						"byd_finger_spi_cs", "byd_reset_high", "byd_reset_low";					
	pinctrl-0 = <&spi_default>;
	pinctrl-1 = <&fp_bf_eint_as_int>;
	pinctrl-2 = <&fp_byd_finger_spi_miso>;
	pinctrl-3 = <&fp_byd_finger_spi_mosi>;
	pinctrl-4 = <&fp_byd_finger_spi_sck>;
	pinctrl-5 = <&fp_byd_finger_spi_cs>;	
	pinctrl-6 = <&fps_byd_reset_high>;
	pinctrl-7 = <&fps_byd_reset_low>;
	interrupt-parent = <&eintc>;
	interrupts = <11 IRQ_TYPE_EDGE_RISING>;
	debounce = <11 0>;
	status = "okay";		
};

&pio {
	spi_default: spi_default {
	};

	fp_bf_eint_as_int: eint@11 {
		pins_cmd_dat {
			pins = <PINMUX_GPIO11__FUNC_EINT11>;
			slew-rate = <0>;
			bias-disable;
		};
	};
	
	fp_byd_finger_spi_miso: fp_byd_finger_spi_miso_cz {
		pins_cmd_dat {
			pins = <PINMUX_GPIO3__FUNC_SPI1_MISO>;
			bias-disable;
		};
	};
	
	fp_byd_finger_spi_mosi: fp_byd_finger_spi_mosi_cz {
		pins_cmd_dat {
			pins = <PINMUX_GPIO2__FUNC_SPI1_MOSI>;
			slew-rate = <1>;
		};
	};
	
	fp_byd_finger_spi_sck: fp_byd_finger_spi_sck_cz {
		pins_cmd_dat {
			pins = <PINMUX_GPIO1__FUNC_SPI1_SCK>;
			slew-rate = <1>;
		};
	};
	
	fp_byd_finger_spi_cs: fp_byd_finger_spi_cs_cz{
		pins_cmd_dat {
			pins = <PINMUX_GPIO0__FUNC_SPI1_CS>;
			slew-rate = <1>;
		};
	};
	
	fps_byd_reset_high: fps_byd_reset_high_cz {
		pins_cmd_dat {
			pins = <PINMUX_GPIO7__FUNC_GPIO7>;
			slew-rate = <1>;
			bias-disable;
			output-high;
		};
	};	

	fps_byd_reset_low: fps_byd_reset_low_cz {
		pins_cmd_dat {
			pins = <PINMUX_GPIO7__FUNC_GPIO7>;
			slew-rate = <1>;
			bias-disable;
			output-low;
		};
	};	
	
};

/*byd add end*/


//add end 
